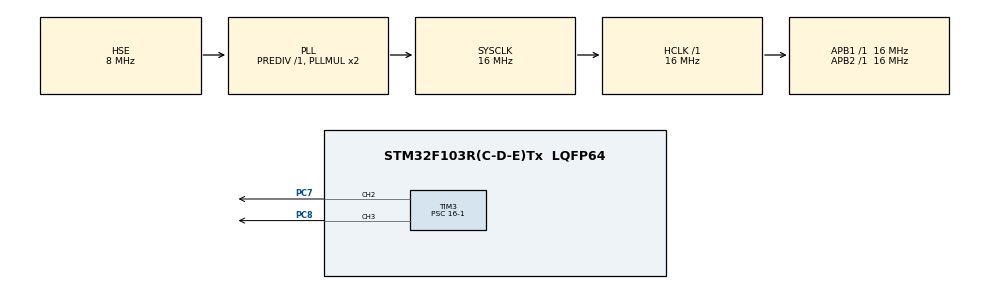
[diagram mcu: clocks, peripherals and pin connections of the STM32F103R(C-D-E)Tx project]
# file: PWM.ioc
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Mcu.Family=STM32F1
Mcu.Name=STM32F103R(C-D-E)Tx
Mcu.Package=LQFP64
NVIC.PriorityGroup=NVIC_PRIORITYGROUP_4
NVIC.TIM3_IRQn=true\:0\:0\:false\:false\:true\:true\:true\:true
PA13.Mode=Serial_Wire
PA13.Signal=SYS_JTMS-SWDIO
PA14.Mode=Serial_Wire
PA14.Signal=SYS_JTCK-SWCLK
PC7.GPIO_Speed=GPIO_SPEED_FREQ_LOW
PC7.Signal=S_TIM3_CH2
PC8.Signal=S_TIM3_CH3
PD0-OSC_IN.Mode=HSE-External-Oscillator
PD0-OSC_IN.Signal=RCC_OSC_IN
PD1-OSC_OUT.Mode=HSE-External-Oscillator
PD1-OSC_OUT.Signal=RCC_OSC_OUT
ProjectManager.HeapSize=0x200
ProjectManager.StackSize=0x400
ProjectManager.TargetToolchain=STM32CubeIDE
RCC.AHBFreq_Value=16000000
RCC.APB1Freq_Value=16000000
RCC.APB1TimFreq_Value=16000000
RCC.APB2Freq_Value=16000000
RCC.APB2TimFreq_Value=16000000
RCC.HCLKFreq_Value=16000000
RCC.PLLSourceVirtual=RCC_PLLSOURCE_HSE
RCC.SYSCLKFreq_VALUE=16000000
RCC.SYSCLKSource=RCC_SYSCLKSOURCE_PLLCLK
RCC.USBFreq_Value=16000000
SH.S_TIM3_CH2.0=TIM3_CH2,PWM Generation2 CH2
SH.S_TIM3_CH3.0=TIM3_CH3,PWM Generation3 CH3
TIM3.AutoReloadPreload=TIM_AUTORELOAD_PRELOAD_ENABLE
TIM3.Channel-PWM\ Generation2\ CH2=TIM_CHANNEL_2
TIM3.Channel-PWM\ Generation3\ CH3=TIM_CHANNEL_3
TIM3.Period=5000
TIM3.Prescaler=16-1
TIM3.Pulse-PWM\ Generation2\ CH2=3750
board=custom

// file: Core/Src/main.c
/* USER CODE BEGIN Header */
/**
  ******************************************************************************
  * @file           : main.c
  * @brief          : Main program body
  ******************************************************************************
  * @attention
  *
  * Copyright (c) 2023 STMicroelectronics.
  * All rights reserved.
  *
  * This software is licensed under terms that can be found in the LICENSE file
  * in the root directory of this software component.
  * If no LICENSE file comes with this software, it is provided AS-IS.
  *
  ******************************************************************************
  */
/* USER CODE END Header */
#include "main.h"
#include "tim.h"
#include "gpio.h"

/* USER CODE BEGIN PV */
uint32_t my_tim3_count;
/* USER CODE END PV */

void SystemClock_Config(void);

int main(void)
{
  /* USER CODE BEGIN 1 */
	int x;
  /* USER CODE END 1 */

  /* MCU Configuration--------------------------------------------------------*/

  /* Reset of all peripherals, Initializes the Flash interface and the Systick. */
  HAL_Init();

  /* Configure the system clock */
  SystemClock_Config();

  /* Initialize all configured peripherals */
  MX_GPIO_Init();
  MX_TIM3_Init();
  /* USER CODE BEGIN 2 */
  HAL_TIM_PWM_Start(&htim3, TIM_CHANNEL_2);
  /* USER CODE END 2 */

  /* Infinite loop */
  while (1)
  {

    /* USER CODE BEGIN 3 */
	  for(x=0;x<=4999;x++)
	  {
		  __HAL_TIM_SET_COMPARE(&htim3,TIM_CHANNEL_2,x);
	  }
	  for(x=4999;x>=0;x--)
	  {
		  __HAL_TIM_SET_COMPARE(&htim3,TIM_CHANNEL_2,x);
	  }

  }
  /* USER CODE END 3 */
}

void SystemClock_Config(void)
{
  RCC_OscInitTypeDef RCC_OscInitStruct = {0};
  RCC_ClkInitTypeDef RCC_ClkInitStruct = {0};

  /** Initializes the RCC Oscillators according to the specified parameters
  * in the RCC_OscInitTypeDef structure.
  */
  RCC_OscInitStruct.OscillatorType = RCC_OSCILLATORTYPE_HSE;
  RCC_OscInitStruct.HSEState = RCC_HSE_ON;
  RCC_OscInitStruct.HSEPredivValue = RCC_HSE_PREDIV_DIV1;
  RCC_OscInitStruct.HSIState = RCC_HSI_ON;
  RCC_OscInitStruct.PLL.PLLState = RCC_PLL_ON;
  RCC_OscInitStruct.PLL.PLLSource = RCC_PLLSOURCE_HSE;
  RCC_OscInitStruct.PLL.PLLMUL = RCC_PLL_MUL2;
  if (HAL_RCC_OscConfig(&RCC_OscInitStruct) != HAL_OK)
  {
    Error_Handler();
  }

  /** Initializes the CPU, AHB and APB buses clocks
  */
  RCC_ClkInitStruct.ClockType = RCC_CLOCKTYPE_HCLK|RCC_CLOCKTYPE_SYSCLK
                              |RCC_CLOCKTYPE_PCLK1|RCC_CLOCKTYPE_PCLK2;
  RCC_ClkInitStruct.SYSCLKSource = RCC_SYSCLKSOURCE_PLLCLK;
  RCC_ClkInitStruct.AHBCLKDivider = RCC_SYSCLK_DIV1;
  RCC_ClkInitStruct.APB1CLKDivider = RCC_HCLK_DIV1;
  RCC_ClkInitStruct.APB2CLKDivider = RCC_HCLK_DIV1;

  if (HAL_RCC_ClockConfig(&RCC_ClkInitStruct, FLASH_LATENCY_0) != HAL_OK)
  {
    Error_Handler();
  }
}

void Error_Handler(void)
{
  __disable_irq();
  while (1)
  {
  }
}
